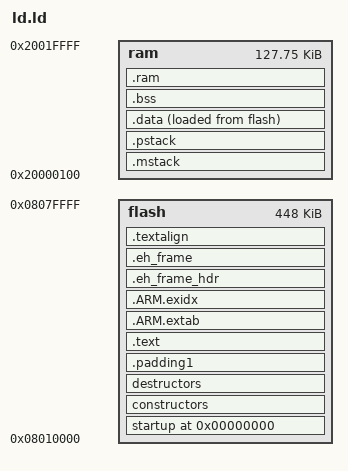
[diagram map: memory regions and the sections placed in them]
/****************************************************************************
*
*   Copyright (C) 2016  Zubax Robotics  <info@zubax.com>
*
* Redistribution and use in source and binary forms, with or without
* modification, are permitted provided that the following conditions
* are met:
*
* 1. Redistributions of source code must retain the above copyright
*    notice, this list of conditions and the following disclaimer.
* 2. Redistributions in binary form must reproduce the above copyright
*    notice, this list of conditions and the following disclaimer in
*    the documentation and/or other materials provided with the
*    distribution.
* 3. Neither the name PX4 nor the names of its contributors may be
*    used to endorse or promote products derived from this software
*    without specific prior written permission.
*
* THIS SOFTWARE IS PROVIDED BY THE COPYRIGHT HOLDERS AND CONTRIBUTORS
* "AS IS" AND ANY EXPRESS OR IMPLIED WARRANTIES, INCLUDING, BUT NOT
* LIMITED TO, THE IMPLIED WARRANTIES OF MERCHANTABILITY AND FITNESS
* FOR A PARTICULAR PURPOSE ARE DISCLAIMED. IN NO EVENT SHALL THE
* COPYRIGHT OWNER OR CONTRIBUTORS BE LIABLE FOR ANY DIRECT, INDIRECT,
* INCIDENTAL, SPECIAL, EXEMPLARY, OR CONSEQUENTIAL DAMAGES (INCLUDING,
* BUT NOT LIMITED TO, PROCUREMENT OF SUBSTITUTE GOODS OR SERVICES; LOSS
* OF USE, DATA, OR PROFITS; OR BUSINESS INTERRUPTION) HOWEVER CAUSED
* AND ON ANY THEORY OF LIABILITY, WHETHER IN CONTRACT, STRICT
* LIABILITY, OR TORT (INCLUDING NEGLIGENCE OR OTHERWISE) ARISING IN
* ANY WAY OUT OF THE USE OF THIS SOFTWARE, EVEN IF ADVISED OF THE
* POSSIBILITY OF SUCH DAMAGE.
*
****************************************************************************/

 /*
  * Based on a ChibiOS demo app.
  */

MEMORY
{
    /*
     * Flash layout:
     *   0K.. 32K    32K    Bootloader
     *  32K.. 48K    16K    Non-volatile storage for configuration parameters
     *  48K.. 64K    16K    Reserved for future use for user-specific code
     *  64K..512K   448K    Application
     */
    flash : org = 0x08010000, len = 448k

    /*
     * RAM layout:
     *    0..256    Reserved space for bootloader-application data exchange
     *  256..128K   Application
     */
    ram   : org = 0x20000100, len = 130816
}


__ram_start__          = ORIGIN(ram);
__ram_size__           = LENGTH(ram);
__ram_end__            = __ram_start__ + __ram_size__;

ENTRY(Reset_Handler)

PROVIDE(DeviceSignatureStorage = (0x08008000 - 256));  /* Right at the end of the space reserved for the bootloader */

SECTIONS
{
    . = 0;
    _text = .;

    startup : ALIGN(16) SUBALIGN(16)
    {
        FILL(0xDEADC0DE);
        KEEP(*(.vectors))
        . = ALIGN(8);
        KEEP(*(.app_descriptor));
        . = ALIGN(8);
    } > flash

    constructors : ALIGN(4) SUBALIGN(4)
    {
        FILL(0xDEADC0DE);
        PROVIDE(__init_array_start = .);
        KEEP(*(SORT(.init_array.*)))
        KEEP(*(.init_array))
        PROVIDE(__init_array_end = .);
    } > flash

    destructors : ALIGN(4) SUBALIGN(4)
    {
        FILL(0xDEADC0DE);
        PROVIDE(__fini_array_start = .);
        KEEP(*(.fini_array))
        KEEP(*(SORT(.fini_array.*)))
        PROVIDE(__fini_array_end = .);
    } > flash

    /*
     * This padding section must be inserted before every section with greater alignment.
     */
    .padding1 :
    {
        /*
         * Filling is important: if it is not specified, gaps between aligned sections will be filled with zero when
         * exporting binaries, and will be skipped (i.e. set to 0xFF) when flashing .elf directly during debugging.
         * The discrepancy causes the firmware CRC to mismatch, preventing the bootloader from running it.
         * Assigning a well-defined fill byte eliminates the discrepancy (binary files will also contain 0xFF or
         * whatever), allowing to flash the firmware directly with an SWD debugger during development.
         * See http://www.math.utah.edu/docs/info/ld_3.html
         * Also http://blog.hrbacek.info/2013/12/28/filling-unused-memory-area-using-gnu-linker-script
         */
        FILL(0xDEADC0DE);
        /* Now, we need some dummy data here, otherwise the alignment above will be ignored. */
        BYTE(0xFF);
        . = ALIGN(64);  /* Text sometimes gets aligned at >32, not sure why */
    } > flash

    .text : ALIGN(16) SUBALIGN(16)
    {
        FILL(0xDEADC0DE);
        *(.text)
        *(.text.*)
        *(.rodata)
        *(.rodata.*)
        *(.glue_7t)
        *(.glue_7)
        *(.gcc*)
    } > flash

    .ARM.extab :
    {
        *(.ARM.extab* .gnu.linkonce.armextab.*)
    } > flash

    .ARM.exidx :
    {
        PROVIDE(__exidx_start = .);
        *(.ARM.exidx* .gnu.linkonce.armexidx.*)
        PROVIDE(__exidx_end = .);
     } > flash

    .eh_frame_hdr :
    {
        *(.eh_frame_hdr)
    } > flash

    .eh_frame : ONLY_IF_RO
    {
        *(.eh_frame)
    } > flash

    .textalign : ONLY_IF_RO
    {
        FILL(0xDEADC0DE);
        BYTE(0xFF);
        . = ALIGN(64);
    } > flash

    . = ALIGN(4);
    _etext = .;
    _textdata_start = _etext;

    .mstack :
    {
        . = ALIGN(8);
        __main_stack_base__ = .;
        . += __main_stack_size__;
        . = ALIGN(8);
        __main_stack_end__ = .;
    } > ram

    .pstack :
    {
        __process_stack_base__ = .;
        __main_thread_stack_base__ = .;
        . += __process_stack_size__;
        . = ALIGN(8);
        __process_stack_end__ = .;
        __main_thread_stack_end__ = .;
    } > ram

    .data : ALIGN(4)
    {
        FILL(0xDEADC0DE);
        . = ALIGN(4);
        PROVIDE(_data_start = .);
        *(.data)
        *(.data.*)
        *(.ramtext)
        . = ALIGN(4);
        PROVIDE(_data_end = .);
    } > ram AT > flash

    .bss : ALIGN(4)
    {
        . = ALIGN(4);
        PROVIDE(_bss_start = .);
        *(.bss)
        *(.bss.*)
        *(COMMON)
        . = ALIGN(4);
        PROVIDE(_bss_end = .);
        PROVIDE(end = .);
    } > ram

    .ram (NOLOAD) : ALIGN(4)
    {
        . = ALIGN(4);
        *(.ram)
        *(.ram.*)
        . = ALIGN(4);
        __ram_free__ = .;
    } > ram
}

/* Heap default boundaries, it is defaulted to be the non-used part of ram region.*/
__heap_base__   = __ram_free__;
__heap_end__    = __ram_end__;

